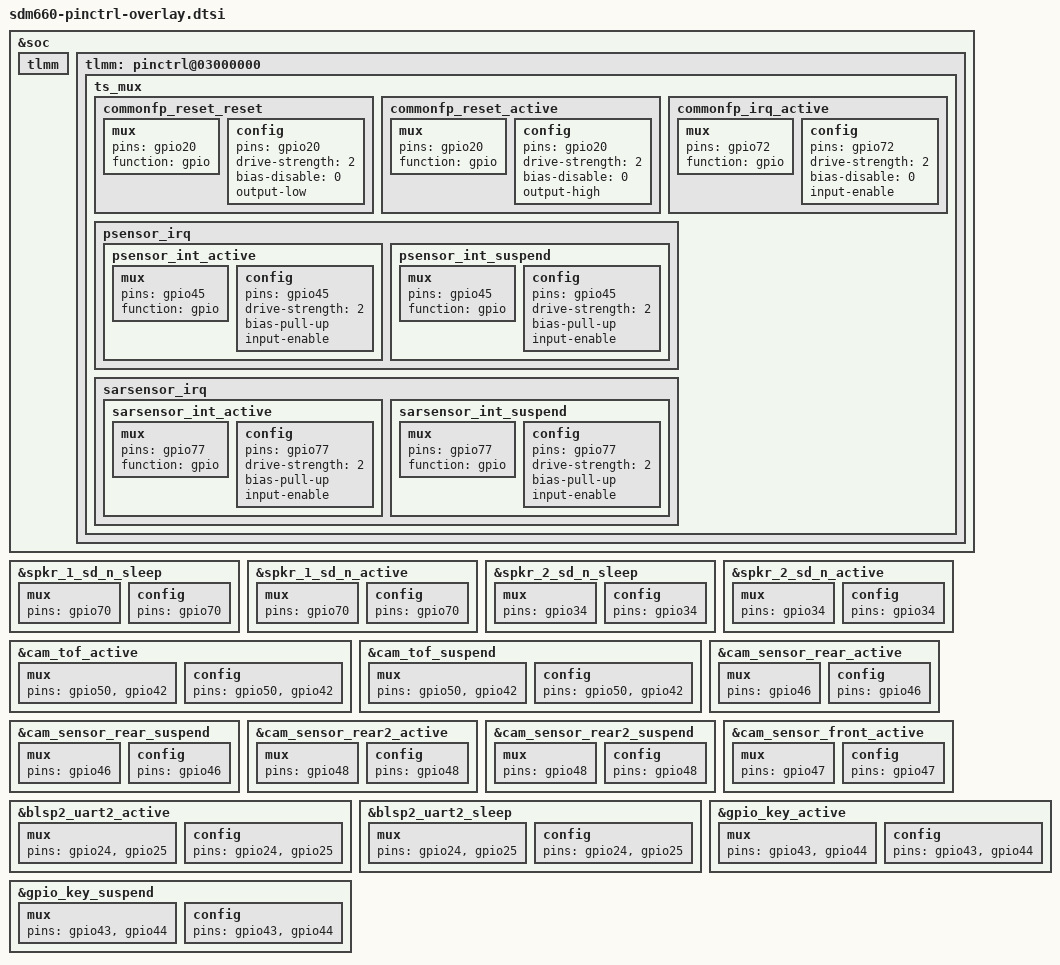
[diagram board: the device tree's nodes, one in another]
/* SPDX-License-Identifier: GPL-2.0 */

&soc {
	tlmm {
		/delete-node/ ufs_dev_reset_assert;
		/delete-node/ ufs_dev_reset_deassert;
	};
};

&spkr_1_sd_n_sleep {
	mux {
		pins = "gpio70";
	};

	config {
		pins = "gpio70";
	};
};

&spkr_1_sd_n_active {
	mux {
		pins = "gpio70";
	};

	config {
		pins = "gpio70";
	};
};

&spkr_2_sd_n_sleep {
	mux {
		pins = "gpio34";
	};

	config {
		pins = "gpio34";
	};
};

&spkr_2_sd_n_active {
	mux {
		pins = "gpio34";
	};

	config {
		pins = "gpio34";
	};
};

&cam_tof_active {
	mux {
		pins = "gpio50", "gpio42";
	};

	config {
		pins = "gpio50", "gpio42";
	};
};

&cam_tof_suspend {
	mux {
		pins = "gpio50", "gpio42";
	};

	config {
		pins = "gpio50", "gpio42";
	};
};

&cam_sensor_rear_active {
	mux {
		pins = "gpio46";
	};

	config {
		pins = "gpio46";
	};
};

&cam_sensor_rear_suspend {
	mux {
		pins = "gpio46";
	};

	config {
		pins = "gpio46";
	};
};

&cam_sensor_rear2_active {
	/* RESET */
	mux {
		pins = "gpio48";
	};

	config {
		pins = "gpio48";
	};
};

&cam_sensor_rear2_suspend {
	/* RESET */
	mux {
		pins = "gpio48";
	};

	config {
		pins = "gpio48";
	};
};

&cam_sensor_front_active {
	mux {
		pins = "gpio47";
	};

	config {
		pins = "gpio47";
	};
};

&blsp2_uart2_active {
	mux {
		pins = "gpio24", "gpio25";
	};

	config {
		pins = "gpio24", "gpio25";
	};
};

&blsp2_uart2_sleep {
	mux {
		pins = "gpio24", "gpio25";
	};

	config {
		pins = "gpio24", "gpio25";
	};
};

&gpio_key_active {
	mux {
		pins = "gpio43", "gpio44";
	};

	config {
		pins = "gpio43", "gpio44";
	};
};

&gpio_key_suspend {
	mux {
		pins = "gpio43", "gpio44";
	};

	config {
		pins = "gpio43", "gpio44";
	};
};

&soc {
	tlmm: pinctrl@03000000 {
		ts_mux {
			commonfp_reset_reset: commonfp_reset_reset {
				mux {
					pins = "gpio20";
					function = "gpio";
				};

				config {
					pins = "gpio20";
					drive-strength = <2>;
					bias-disable = <0>;
					output-low;
				};
			};

			commonfp_reset_active: commonfp_reset_active {
				mux {
					pins = "gpio20";
					function = "gpio";
				};

				config {
					pins = "gpio20";
					drive-strength = <2>;
					bias-disable = <0>;
					output-high;
				};
			};

			commonfp_irq_active: commonfp_irq_active {
				mux {
					pins = "gpio72";
					function = "gpio";
				};

				config {
					pins = "gpio72";
					drive-strength = <2>;
					bias-disable = <0>;
					input-enable;
				};
			};

			psensor_irq {
				psensor_int_active: psensor_int_active {
					mux {
						pins = "gpio45";
						function = "gpio";
					};

					config {
						pins = "gpio45";
						drive-strength = <2>;
						bias-pull-up;
						input-enable;
					};
				};

				psensor_int_suspend: psensor_int_suspend {
					mux {
						pins = "gpio45";
						function = "gpio";
					};

					config {
						pins = "gpio45";
						drive-strength = <2>;
						bias-pull-up;
						input-enable;
					};
				};
			};

			sarsensor_irq {
				sarsensor_int_active: sarsensor_int_active {
					mux {
						pins = "gpio77";
						function = "gpio";
					};

					config {
						pins = "gpio77";
						drive-strength = <2>;
						bias-pull-up;
						input-enable;
					};
				};

				sarsensor_int_suspend: sarsensor_int_suspend {
					mux {
						pins = "gpio77";
						function = "gpio";
					};

					config {
						pins = "gpio77";
						drive-strength = <2>;
						bias-pull-up;
						input-enable;
					};
				};
			};
		};
	};
};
